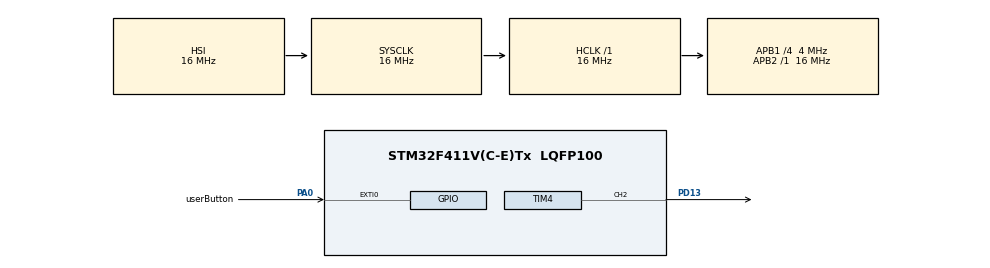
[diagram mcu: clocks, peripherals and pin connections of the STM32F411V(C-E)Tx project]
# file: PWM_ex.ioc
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Mcu.Family=STM32F4
Mcu.Name=STM32F411V(C-E)Tx
Mcu.Package=LQFP100
NVIC.EXTI0_IRQn=true\:15\:0\:true\:false\:true\:true\:true\:true
NVIC.PriorityGroup=NVIC_PRIORITYGROUP_4
PA0-WKUP.GPIO_Label=userButton
PA0-WKUP.GPIO_PuPd=GPIO_PULLDOWN
PA0-WKUP.Signal=GPXTI0
PA13.Mode=Serial_Wire
PA13.Signal=SYS_JTMS-SWDIO
PA14.Mode=Serial_Wire
PA14.Signal=SYS_JTCK-SWCLK
PD13.Signal=S_TIM4_CH2
ProjectManager.HeapSize=0x200
ProjectManager.StackSize=0x400
ProjectManager.TargetToolchain=STM32CubeIDE
RCC.AHBFreq_Value=16000000
RCC.APB1CLKDivider=RCC_HCLK_DIV4
RCC.APB1Freq_Value=4000000
RCC.APB1TimFreq_Value=8000000
RCC.APB2Freq_Value=16000000
RCC.APB2TimFreq_Value=16000000
RCC.CortexFreq_Value=16000000
RCC.HCLKFreq_Value=16000000
RCC.HSE_VALUE=25000000
RCC.HSI_VALUE=16000000
RCC.LSE_VALUE=32768
RCC.SYSCLKFreq_VALUE=16000000
RCC.VCOOutputFreq_Value=192000000
SH.S_TIM4_CH2.0=TIM4_CH2,PWM Generation2 CH2
TIM4.Channel-PWM\ Generation2\ CH2=TIM_CHANNEL_2
TIM4.Period=99
TIM4.Prescaler=7
VP_TIM4_VS_ClockSourceINT.Mode=Internal
board=custom

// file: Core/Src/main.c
/* USER CODE BEGIN Header */
/**
  ******************************************************************************
  * @file           : main.c
  * @brief          : Main program body
  ******************************************************************************
  * @attention
  *
  * Copyright (c) 2023 STMicroelectronics.
  * All rights reserved.
  *
  * This software is licensed under terms that can be found in the LICENSE file
  * in the root directory of this software component.
  * If no LICENSE file comes with this software, it is provided AS-IS.
  *
  ******************************************************************************
  */
/* USER CODE END Header */
#include "main.h"

TIM_HandleTypeDef htim4;

/* USER CODE BEGIN PV */
uint8_t dutyCycle = 0;
int8_t dir = 1;
/* USER CODE END PV */

void SystemClock_Config(void);
static void MX_GPIO_Init(void);
static void MX_TIM4_Init(void);

/* Private user code -------	--------------------------------------------------*/
/* USER CODE BEGIN 0 */
void HAL_GPIO_EXTI_Callback(uint16_t GPIO_Pin)
{
	if (GPIO_Pin == GPIO_PIN_0) {
		dutyCycle = dutyCycle + dir*20;

		if (dutyCycle == 100)
			dir = -1;
		else if (dutyCycle == 0)
			dir = 1;
	}

	__HAL_TIM_SET_COMPARE(&htim4, TIM_CHANNEL_2, dutyCycle);

	// Debounce
	HAL_Delay(20);
	uint32_t currentTime = HAL_GetTick();
	while (HAL_GPIO_ReadPin(GPIOA, GPIO_PIN_0) == GPIO_PIN_SET) {
		if (HAL_GetTick() - currentTime > 1000)
			break;
	}
	HAL_Delay(20);
	__HAL_GPIO_EXTI_CLEAR_IT(GPIO_Pin);

}
/* USER CODE END 0 */

int main(void)
{

  /* MCU Configuration--------------------------------------------------------*/

  /* Reset of all peripherals, Initializes the Flash interface and the Systick. */
  HAL_Init();

  /* Configure the system clock */
  SystemClock_Config();

  /* Initialize all configured peripherals */
  MX_GPIO_Init();
  MX_TIM4_Init();
  /* USER CODE BEGIN 2 */
  HAL_TIM_PWM_Start(&htim4, TIM_CHANNEL_2);

  /* USER CODE END 2 */

  /* Infinite loop */
  while (1)
  {

  }
}

void SystemClock_Config(void)
{
  RCC_OscInitTypeDef RCC_OscInitStruct = {0};
  RCC_ClkInitTypeDef RCC_ClkInitStruct = {0};

  /** Configure the main internal regulator output voltage
  */
  __HAL_RCC_PWR_CLK_ENABLE();
  __HAL_PWR_VOLTAGESCALING_CONFIG(PWR_REGULATOR_VOLTAGE_SCALE1);

  /** Initializes the RCC Oscillators according to the specified parameters
  * in the RCC_OscInitTypeDef structure.
  */
  RCC_OscInitStruct.OscillatorType = RCC_OSCILLATORTYPE_HSI;
  RCC_OscInitStruct.HSIState = RCC_HSI_ON;
  RCC_OscInitStruct.HSICalibrationValue = RCC_HSICALIBRATION_DEFAULT;
  RCC_OscInitStruct.PLL.PLLState = RCC_PLL_NONE;
  if (HAL_RCC_OscConfig(&RCC_OscInitStruct) != HAL_OK)
  {
    Error_Handler();
  }

  /** Initializes the CPU, AHB and APB buses clocks
  */
  RCC_ClkInitStruct.ClockType = RCC_CLOCKTYPE_HCLK|RCC_CLOCKTYPE_SYSCLK
                              |RCC_CLOCKTYPE_PCLK1|RCC_CLOCKTYPE_PCLK2;
  RCC_ClkInitStruct.SYSCLKSource = RCC_SYSCLKSOURCE_HSI;
  RCC_ClkInitStruct.AHBCLKDivider = RCC_SYSCLK_DIV1;
  RCC_ClkInitStruct.APB1CLKDivider = RCC_HCLK_DIV4;
  RCC_ClkInitStruct.APB2CLKDivider = RCC_HCLK_DIV1;

  if (HAL_RCC_ClockConfig(&RCC_ClkInitStruct, FLASH_LATENCY_0) != HAL_OK)
  {
    Error_Handler();
  }
}

static void MX_TIM4_Init(void)
{

  TIM_ClockConfigTypeDef sClockSourceConfig = {0};
  TIM_MasterConfigTypeDef sMasterConfig = {0};
  TIM_OC_InitTypeDef sConfigOC = {0};

  htim4.Instance = TIM4;
  htim4.Init.Prescaler = 7;
  htim4.Init.CounterMode = TIM_COUNTERMODE_UP;
  htim4.Init.Period = 99;
  htim4.Init.ClockDivision = TIM_CLOCKDIVISION_DIV1;
  htim4.Init.AutoReloadPreload = TIM_AUTORELOAD_PRELOAD_DISABLE;
  if (HAL_TIM_Base_Init(&htim4) != HAL_OK)
  {
    Error_Handler();
  }
  sClockSourceConfig.ClockSource = TIM_CLOCKSOURCE_INTERNAL;
  if (HAL_TIM_ConfigClockSource(&htim4, &sClockSourceConfig) != HAL_OK)
  {
    Error_Handler();
  }
  if (HAL_TIM_PWM_Init(&htim4) != HAL_OK)
  {
    Error_Handler();
  }
  sMasterConfig.MasterOutputTrigger = TIM_TRGO_RESET;
  sMasterConfig.MasterSlaveMode = TIM_MASTERSLAVEMODE_DISABLE;
  if (HAL_TIMEx_MasterConfigSynchronization(&htim4, &sMasterConfig) != HAL_OK)
  {
    Error_Handler();
  }
  sConfigOC.OCMode = TIM_OCMODE_PWM1;
  sConfigOC.Pulse = 0;
  sConfigOC.OCPolarity = TIM_OCPOLARITY_HIGH;
  sConfigOC.OCFastMode = TIM_OCFAST_DISABLE;
  if (HAL_TIM_PWM_ConfigChannel(&htim4, &sConfigOC, TIM_CHANNEL_2) != HAL_OK)
  {
    Error_Handler();
  }
  HAL_TIM_MspPostInit(&htim4);

}

static void MX_GPIO_Init(void)
{
  GPIO_InitTypeDef GPIO_InitStruct = {0};

  /* GPIO Ports Clock Enable */
  __HAL_RCC_GPIOA_CLK_ENABLE();
  __HAL_RCC_GPIOD_CLK_ENABLE();

  /*Configure GPIO pin : userButton_Pin */
  GPIO_InitStruct.Pin = userButton_Pin;
  GPIO_InitStruct.Mode = GPIO_MODE_IT_RISING;
  GPIO_InitStruct.Pull = GPIO_PULLDOWN;
  HAL_GPIO_Init(userButton_GPIO_Port, &GPIO_InitStruct);

  /* EXTI interrupt init*/
  HAL_NVIC_SetPriority(EXTI0_IRQn, 15, 0);
  HAL_NVIC_EnableIRQ(EXTI0_IRQn);

}

void Error_Handler(void)
{
  __disable_irq();
  while (1)
  {
  }
}
